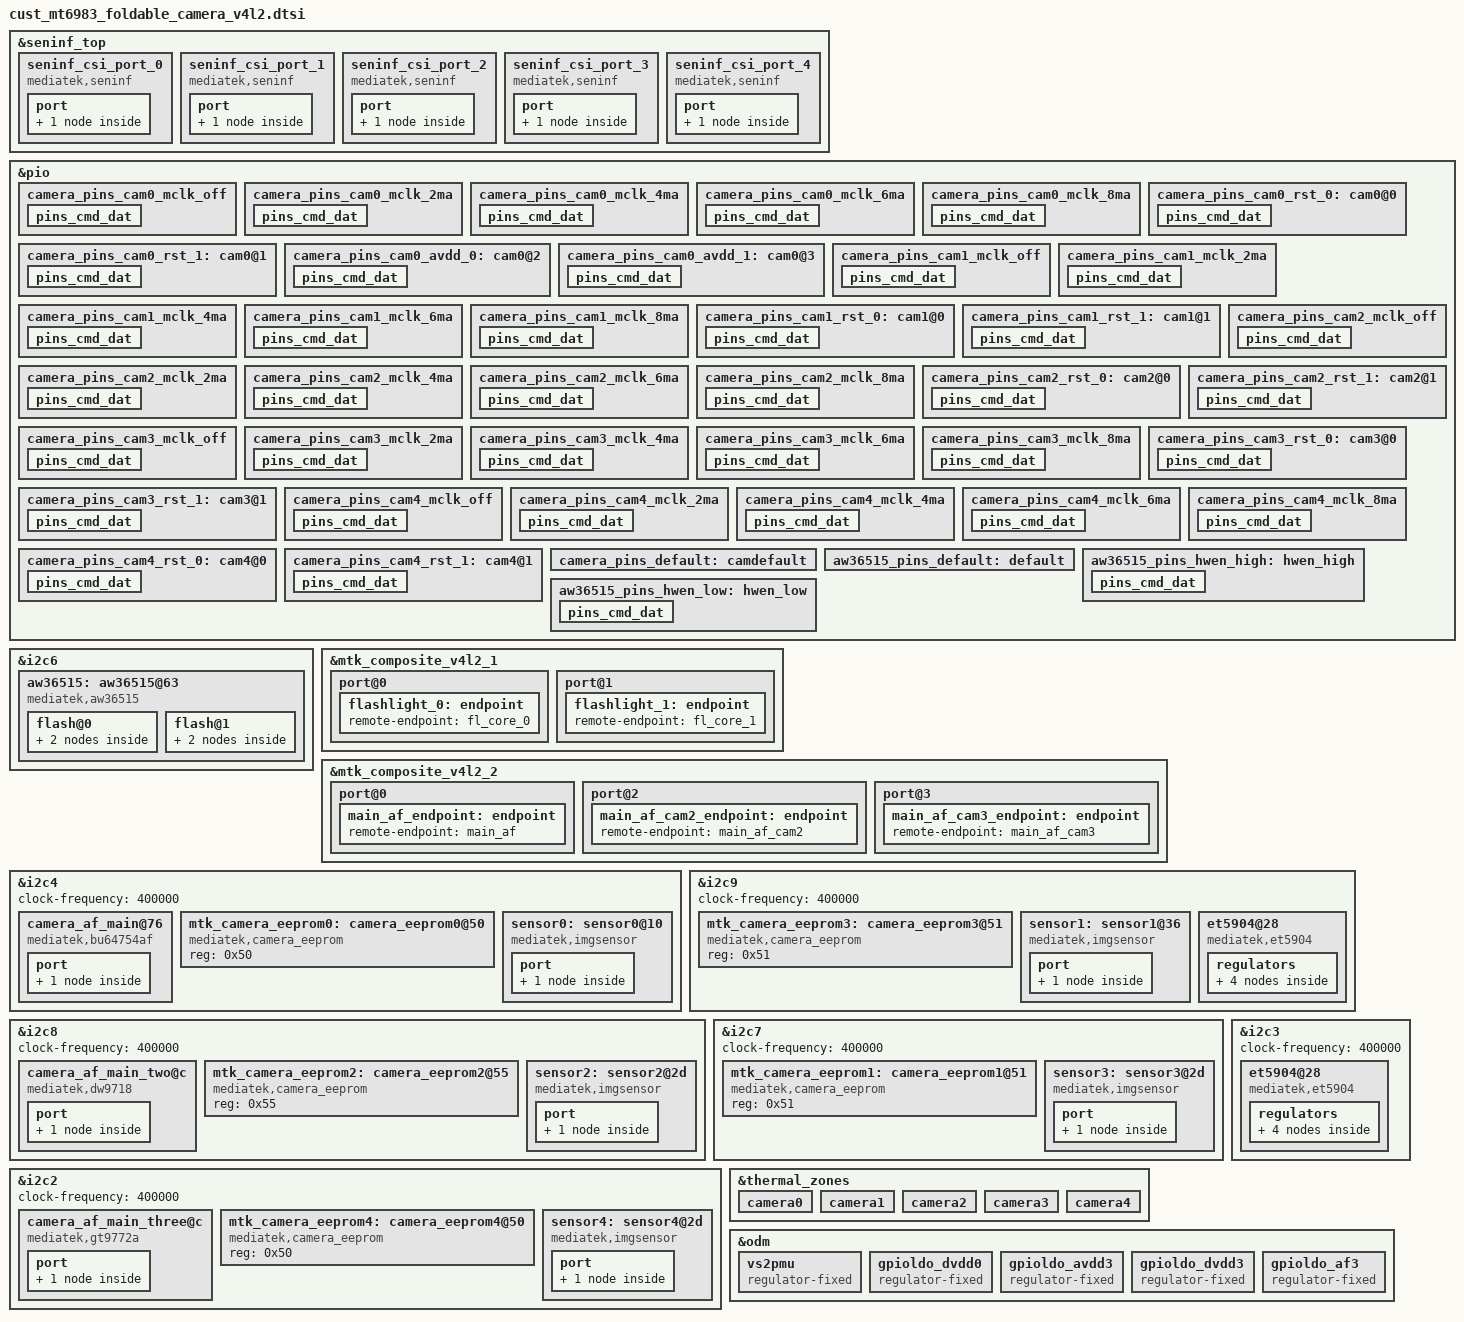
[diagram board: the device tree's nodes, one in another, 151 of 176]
// SPDX-License-Identifier: GPL-2.0
/* Copyright (c) 2020 MediaTek Inc. */

&seninf_top {
		seninf_csi_port_0: seninf_csi_port_0 {
			compatible = "mediatek,seninf";
			csi-port = "0";
			dphy_settle_delay_dt = <17>;
			nvmem-cells = <&csi_efuse0>;
			nvmem-cell-names = "rg_csi";
			port {
				seninf_csi_port_0_in: endpoint {
					remote-endpoint = <&sensor3_out>;
				};
			};
		};

		seninf_csi_port_1: seninf_csi_port_1 {
			compatible = "mediatek,seninf";
			csi-port = "1";
			hs_trail_parameter = <0x20>;
			nvmem-cells = <&csi_efuse1>;
			nvmem-cell-names = "rg_csi";
			port {
				seninf_csi_port_1_in: endpoint {
					remote-endpoint = <&sensor1_out>;
				};
			};
		};
		seninf_csi_port_2: seninf_csi_port_2 {
			compatible = "mediatek,seninf";
			csi-port = "2";
			hs_trail_parameter = <0x20>;
			nvmem-cells = <&csi_efuse2>;
			nvmem-cell-names = "rg_csi";
			port {
				seninf_csi_port_2_in: endpoint {
					remote-endpoint = <&sensor4_out>;
				};
			};
		};
		seninf_csi_port_3: seninf_csi_port_3 {
			compatible = "mediatek,seninf";
			csi-port = "3";
			nvmem-cells = <&csi_efuse3>;
			nvmem-cell-names = "rg_csi";
			port {
				seninf_csi_port_3_in: endpoint {
					remote-endpoint = <&sensor0_out>;
				};
			};
		};
		seninf_csi_port_4: seninf_csi_port_4 {
			compatible = "mediatek,seninf";
			csi-port = "4";
			nvmem-cells = <&csi_efuse1>;
			nvmem-cell-names = "rg_csi";
			port {
				seninf_csi_port_4_in: endpoint {
					remote-endpoint = <&sensor2_out>;
				};
			};
		};
};
/* CAMERA GPIO standardization */
&pio {
	camera_pins_cam0_mclk_off: camera_pins_cam0_mclk_off {
		pins_cmd_dat {
			pinmux = <PINMUX_GPIO197__FUNC_GPIO197>;
			drive-strength = <1>;
		};
	};
	camera_pins_cam0_mclk_2ma: camera_pins_cam0_mclk_2ma {
		pins_cmd_dat {
			pinmux = <PINMUX_GPIO197__FUNC_CMMCLK1>;
			drive-strength = <0>;
		};
	};
	camera_pins_cam0_mclk_4ma: camera_pins_cam0_mclk_4ma {
		pins_cmd_dat {
			pinmux = <PINMUX_GPIO197__FUNC_CMMCLK1>;
			drive-strength = <1>;
		};
	};
	camera_pins_cam0_mclk_6ma: camera_pins_cam0_mclk_6ma {
		pins_cmd_dat {
			pinmux = <PINMUX_GPIO197__FUNC_CMMCLK1>;
			drive-strength = <2>;
		};
	};
	camera_pins_cam0_mclk_8ma: camera_pins_cam0_mclk_8ma {
		pins_cmd_dat {
			pinmux = <PINMUX_GPIO197__FUNC_CMMCLK1>;
			drive-strength = <3>;
		};
	};
	camera_pins_cam0_rst_0: cam0@0 {
		pins_cmd_dat {
			pinmux = <PINMUX_GPIO200__FUNC_GPIO200>;
			slew-rate = <1>;
			output-low;
		};
	};
	camera_pins_cam0_rst_1: cam0@1 {
		pins_cmd_dat {
			pinmux = <PINMUX_GPIO200__FUNC_GPIO200>;
			slew-rate = <1>;
			output-high;
		};
	};
	camera_pins_cam0_avdd_0: cam0@2 {
		pins_cmd_dat {
			pinmux = <PINMUX_GPIO188__FUNC_GPIO188>;
			slew-rate = <1>;
			output-low;
		};
	};
	camera_pins_cam0_avdd_1: cam0@3 {
		pins_cmd_dat {
			pinmux = <PINMUX_GPIO188__FUNC_GPIO188>;
			slew-rate = <1>;
			output-high;
		};
	};

	camera_pins_cam1_mclk_off: camera_pins_cam1_mclk_off {
		pins_cmd_dat {
			pinmux = <PINMUX_GPIO209__FUNC_GPIO209>;
			drive-strength = <1>;
		};
	};
	camera_pins_cam1_mclk_2ma: camera_pins_cam1_mclk_2ma {
		pins_cmd_dat {
			pinmux = <PINMUX_GPIO209__FUNC_CMMCLK4>;
			drive-strength = <0>;
		};
	};
	camera_pins_cam1_mclk_4ma: camera_pins_cam1_mclk_4ma {
		pins_cmd_dat {
			pinmux = <PINMUX_GPIO209__FUNC_CMMCLK4>;
			drive-strength = <1>;
		};
	};
	camera_pins_cam1_mclk_6ma: camera_pins_cam1_mclk_6ma {
		pins_cmd_dat {
			pinmux = <PINMUX_GPIO209__FUNC_CMMCLK4>;
			drive-strength = <2>;
		};
	};
	camera_pins_cam1_mclk_8ma: camera_pins_cam1_mclk_8ma {
		pins_cmd_dat {
			pinmux = <PINMUX_GPIO209__FUNC_CMMCLK4>;
			drive-strength = <3>;
		};
	};
	camera_pins_cam1_rst_0: cam1@0 {
		pins_cmd_dat {
			pinmux = <PINMUX_GPIO203__FUNC_GPIO203>;
			slew-rate = <1>;
			output-low;
		};
	};
	camera_pins_cam1_rst_1: cam1@1 {
		pins_cmd_dat {
			pinmux = <PINMUX_GPIO203__FUNC_GPIO203>;
			slew-rate = <1>;
			output-high;
		};
	};

	camera_pins_cam2_mclk_off: camera_pins_cam2_mclk_off {
		pins_cmd_dat {
			pinmux = <PINMUX_GPIO198__FUNC_GPIO198>;
			drive-strength = <1>;
		};
	};
	camera_pins_cam2_mclk_2ma: camera_pins_cam2_mclk_2ma {
		pins_cmd_dat {
			pinmux = <PINMUX_GPIO198__FUNC_CMMCLK2>;
			drive-strength = <0>;
		};
	};
	camera_pins_cam2_mclk_4ma: camera_pins_cam2_mclk_4ma {
		pins_cmd_dat {
			pinmux = <PINMUX_GPIO198__FUNC_CMMCLK2>;
			drive-strength = <1>;
		};
	};
	camera_pins_cam2_mclk_6ma: camera_pins_cam2_mclk_6ma {
		pins_cmd_dat {
			pinmux = <PINMUX_GPIO198__FUNC_CMMCLK2>;
			drive-strength = <2>;
		};
	};
	camera_pins_cam2_mclk_8ma: camera_pins_cam2_mclk_8ma {
		pins_cmd_dat {
			pinmux = <PINMUX_GPIO198__FUNC_CMMCLK2>;
			drive-strength = <3>;
		};
	};
	camera_pins_cam2_rst_0: cam2@0 {
		pins_cmd_dat {
			pinmux = <PINMUX_GPIO201__FUNC_GPIO201>;
			slew-rate = <1>;
			output-low;
		};
	};
	camera_pins_cam2_rst_1: cam2@1 {
		pins_cmd_dat {
			pinmux = <PINMUX_GPIO201__FUNC_GPIO201>;
			slew-rate = <1>;
			output-high;
		};
	};

	camera_pins_cam3_mclk_off: camera_pins_cam3_mclk_off {
		pins_cmd_dat {
			pinmux = <PINMUX_GPIO196__FUNC_GPIO196>;
			drive-strength = <1>;
		};
	};
	camera_pins_cam3_mclk_2ma: camera_pins_cam3_mclk_2ma {
		pins_cmd_dat {
			pinmux = <PINMUX_GPIO196__FUNC_CMMCLK0>;
			drive-strength = <0>;
		};
	};
	camera_pins_cam3_mclk_4ma: camera_pins_cam3_mclk_4ma {
		pins_cmd_dat {
			pinmux = <PINMUX_GPIO196__FUNC_CMMCLK0>;
			drive-strength = <1>;
		};
	};
	camera_pins_cam3_mclk_6ma: camera_pins_cam3_mclk_6ma {
		pins_cmd_dat {
			pinmux = <PINMUX_GPIO196__FUNC_CMMCLK0>;
			drive-strength = <2>;
		};
	};
	camera_pins_cam3_mclk_8ma: camera_pins_cam3_mclk_8ma {
		pins_cmd_dat {
			pinmux = <PINMUX_GPIO196__FUNC_CMMCLK0>;
			drive-strength = <3>;
		};
	};
	camera_pins_cam3_rst_0: cam3@0 {
		pins_cmd_dat {
			pinmux = <PINMUX_GPIO199__FUNC_GPIO199>;
			slew-rate = <1>;
			output-low;
		};
	};
	camera_pins_cam3_rst_1: cam3@1 {
		pins_cmd_dat {
			pinmux = <PINMUX_GPIO199__FUNC_GPIO199>;
			slew-rate = <1>;
			output-high;
		};
	};

	camera_pins_cam4_mclk_off: camera_pins_cam4_mclk_off {
		pins_cmd_dat {
			pinmux = <PINMUX_GPIO208__FUNC_GPIO208>;
			drive-strength = <1>;
		};
	};
	camera_pins_cam4_mclk_2ma: camera_pins_cam4_mclk_2ma {
		pins_cmd_dat {
			pinmux = <PINMUX_GPIO208__FUNC_CMMCLK3>;
			drive-strength = <0>;
		};
	};
	camera_pins_cam4_mclk_4ma: camera_pins_cam4_mclk_4ma {
		pins_cmd_dat {
			pinmux = <PINMUX_GPIO208__FUNC_CMMCLK3>;
			drive-strength = <1>;
		};
	};
	camera_pins_cam4_mclk_6ma: camera_pins_cam4_mclk_6ma {
		pins_cmd_dat {
			pinmux = <PINMUX_GPIO208__FUNC_CMMCLK3>;
			drive-strength = <2>;
		};
	};
	camera_pins_cam4_mclk_8ma: camera_pins_cam4_mclk_8ma {
		pins_cmd_dat {
			pinmux = <PINMUX_GPIO208__FUNC_CMMCLK3>;
			drive-strength = <3>;
		};
	};
	camera_pins_cam4_rst_0: cam4@0 {
		pins_cmd_dat {
			pinmux = <PINMUX_GPIO202__FUNC_GPIO202>;
			slew-rate = <1>;
			output-low;
		};
	};
	camera_pins_cam4_rst_1: cam4@1 {
		pins_cmd_dat {
			pinmux = <PINMUX_GPIO202__FUNC_GPIO202>;
			slew-rate = <1>;
			output-high;
		};
	};
	camera_pins_default: camdefault {
	};
};
/* CAMERA GPIO end */

&i2c6 {
	aw36515:aw36515@63 {
		compatible = "mediatek,aw36515";
		reg = <0x63>;
		#cooling-cells = <2>;
		pinctrl-names = "default", "hwen_high", "hwen_low";
		pinctrl-0 = <&aw36515_pins_default>;
		pinctrl-1 = <&aw36515_pins_hwen_high>;
		pinctrl-2 = <&aw36515_pins_hwen_low>;
		status = "okay";
		flash@0{
			reg = <1>;
			type = <1>;
			ct = <0>;
			part = <0>;
			port@0 {
				fl_core_0: endpoint {
					remote-endpoint = <&flashlight_0>;
				};
			};
		};
		flash@1{
			reg = <0>;
			type = <0>;
			ct = <0>;
			part = <0>;
			port@1 {
				fl_core_1: endpoint {
					remote-endpoint = <&flashlight_1>;
				};
			};
		};
	};
};

&pio {
	aw36515_pins_default: default {
	};

	aw36515_pins_hwen_high: hwen_high {
		pins_cmd_dat {
			pinmux = <PINMUX_GPIO31__FUNC_GPIO31>;
			slew-rate = <1>;
			output-high;
		};
	};

	aw36515_pins_hwen_low: hwen_low {
		pins_cmd_dat {
			pinmux = <PINMUX_GPIO31__FUNC_GPIO31>;
			slew-rate = <1>;
			output-low;
		};
	};
};

&mtk_composite_v4l2_1 {
	port@0 {
		flashlight_0: endpoint {
			remote-endpoint = <&fl_core_0>;
		};
	};
	port@1 {
		flashlight_1: endpoint {
			remote-endpoint = <&fl_core_1>;
		};
	};
};

&mtk_composite_v4l2_2 {
	port@0 {
		main_af_endpoint: endpoint {
			remote-endpoint = <&main_af>;
		};
	};
	port@2 {
		main_af_cam2_endpoint: endpoint {
			remote-endpoint = <&main_af_cam2>;
		};
	};
	port@3 {
		main_af_cam3_endpoint: endpoint {
			remote-endpoint = <&main_af_cam3>;
		};
	};
};

&i2c4 {
	status = "okay";
	clock-frequency = <400000>;
	#address-cells = <1>;
	#size-cells = <0>;

	camera_af_main@76 {
		compatible = "mediatek,bu64754af";
		reg = <0x76>;
		vin-supply = <&mt6373_vibr>;
		port {
			main_af: endpoint {
				remote-endpoint = <&main_af_endpoint>;
			};
		};
	};
	mtk_camera_eeprom0:camera_eeprom0@50 {
		compatible = "mediatek,camera_eeprom";
		reg = <0x50>;
		status = "okay";
	};

	sensor0: sensor0@10 {
		compatible = "mediatek,imgsensor";
		sensor-names = "s5kgnvsp_mipi_raw";
		reg = <0x10>;
		#thermal-sensor-cells = <0>;
		sensor-matecodes = "s5kgnvsp_17201758";
		pinctrl-names = "mclk_off",
				"mclk_2mA",
				"mclk_4mA",
				"mclk_6mA",
				"mclk_8mA",
				"rst_low",
				"rst_high",
				"avdd_off",
				"avdd_on";

		pinctrl-0 = <&camera_pins_cam0_mclk_off>;
		pinctrl-1 = <&camera_pins_cam0_mclk_2ma>;
		pinctrl-2 = <&camera_pins_cam0_mclk_4ma>;
		pinctrl-3 = <&camera_pins_cam0_mclk_6ma>;
		pinctrl-4 = <&camera_pins_cam0_mclk_8ma>;
		pinctrl-5 = <&camera_pins_cam0_rst_0>;
		pinctrl-6 = <&camera_pins_cam0_rst_1>;
		pinctrl-7 = <&camera_pins_cam0_avdd_0>;
		pinctrl-8 = <&camera_pins_cam0_avdd_1>;

		dvdd-supply = <&gpioldo_dvdd0>;
		dovdd-supply = <&mt6373_vaud18>;

		clocks = <&topckgen_clk CLK_TOPCKGEN_UNIVPLL_192M_D32>,
			<&topckgen_clk CLK_TOPCKGEN_UNIVPLL_192M_D16>,
			<&topckgen_clk CLK_TOPCKGEN_F_F26M_CK_D2>,
			<&topckgen_clk CLK_TOPCKGEN_UNIVPLL_192M_D10>,
			<&topckgen_clk CLK_TOPCKGEN_UNIVPLL_192M_D8>,
			<&topckgen_clk CLK_TOP_TCK_26M_MX9>,
			<&topckgen_clk CLK_TOPCKGEN_UNIVPLL_D6_D8>,
			<&topckgen_clk CLK_TOPCKGEN_CAMTG2_SEL>;
		clock-names = "6", "12", "13", "19.2", "24", "26", "52", "mclk";

		status = "okay";

		port {
			sensor0_out: endpoint {
				remote-endpoint = <&seninf_csi_port_3_in>;
			};
		};
	};
};

&i2c9 {
	status = "okay";
	clock-frequency = <400000>;
	#address-cells = <1>;
	#size-cells = <0>;

	mtk_camera_eeprom3:camera_eeprom3@51 {
		compatible = "mediatek,camera_eeprom";
		reg = <0x51>;
		status = "okay";
	};

	sensor1: sensor1@36 {
		compatible = "mediatek,imgsensor";
		sensor-names = "ov16b10ff_mipi_raw";
		reg = <0x36>;
		sensor-matecodes = "ov16b10_17201705";
		#thermal-sensor-cells = <0>;
		pinctrl-names = "mclk_off",
				"mclk_2mA",
				"mclk_4mA",
				"mclk_6mA",
				"mclk_8mA",
				"rst_low",
				"rst_high";

		pinctrl-0 = <&camera_pins_cam1_mclk_off>;
		pinctrl-1 = <&camera_pins_cam1_mclk_2ma>;
		pinctrl-2 = <&camera_pins_cam1_mclk_4ma>;
		pinctrl-3 = <&camera_pins_cam1_mclk_6ma>;
		pinctrl-4 = <&camera_pins_cam1_mclk_8ma>;
		pinctrl-5 = <&camera_pins_cam1_rst_0>;
		pinctrl-6 = <&camera_pins_cam1_rst_1>;

		avdd-supply = <&et5904ldo39>;
		dvdd-supply = <&et5904ldo19>;
		dovdd-supply = <&mt6373_vaud18>;

		clocks = <&topckgen_clk CLK_TOPCKGEN_UNIVPLL_192M_D32>,
			<&topckgen_clk CLK_TOPCKGEN_UNIVPLL_192M_D16>,
			<&topckgen_clk CLK_TOPCKGEN_F_F26M_CK_D2>,
			<&topckgen_clk CLK_TOPCKGEN_UNIVPLL_192M_D10>,
			<&topckgen_clk CLK_TOPCKGEN_UNIVPLL_192M_D8>,
			<&topckgen_clk CLK_TOP_TCK_26M_MX9>,
			<&topckgen_clk CLK_TOPCKGEN_UNIVPLL_D6_D8>,
			<&topckgen_clk CLK_TOPCKGEN_CAMTG5_SEL>;
		clock-names = "6", "12", "13", "19.2", "24", "26", "52", "mclk";

		status = "okay";

		port {
			sensor1_out: endpoint {
				remote-endpoint = <&seninf_csi_port_1_in>;
			};
		};
	};
};

&i2c8 {
	status = "okay";
	clock-frequency = <400000>;
	#address-cells = <1>;
	#size-cells = <0>;

	camera_af_main_two@c {
		compatible = "mediatek,dw9718";
		reg = <0x0c>;
		vin-supply = <&et5904ldo43>;
		port {
			main_af_cam2: endpoint {
				remote-endpoint = <&main_af_cam2_endpoint>;
			};
		};
	};

	mtk_camera_eeprom2:camera_eeprom2@55 {
		compatible = "mediatek,camera_eeprom";
		reg = <0x55>;
		status = "okay";
	};

	sensor2: sensor2@2d {
		compatible = "mediatek,imgsensor";
		sensor-names = "s5kjn1tele_mipi_raw";
		reg = <0x2d>;
		sensor-matecodes = "s5kjn1tele_17201764";
		#thermal-sensor-cells = <0>;
		pinctrl-names = "mclk_off",
				"mclk_2mA",
				"mclk_4mA",
				"mclk_6mA",
				"mclk_8mA",
				"rst_low",
				"rst_high";

		pinctrl-0 = <&camera_pins_cam2_mclk_off>;
		pinctrl-1 = <&camera_pins_cam2_mclk_2ma>;
		pinctrl-2 = <&camera_pins_cam2_mclk_4ma>;
		pinctrl-3 = <&camera_pins_cam2_mclk_6ma>;
		pinctrl-4 = <&camera_pins_cam2_mclk_8ma>;
		pinctrl-5 = <&camera_pins_cam2_rst_0>;
		pinctrl-6 = <&camera_pins_cam2_rst_1>;

		avdd-supply = <&et5904ldo49>;
		dvdd-supply = <&et5904ldo29>;
		dovdd-supply = <&mt6373_vaud18>;

		clocks = <&topckgen_clk CLK_TOPCKGEN_UNIVPLL_192M_D32>,
			<&topckgen_clk CLK_TOPCKGEN_UNIVPLL_192M_D16>,
			<&topckgen_clk CLK_TOPCKGEN_F_F26M_CK_D2>,
			<&topckgen_clk CLK_TOPCKGEN_UNIVPLL_192M_D10>,
			<&topckgen_clk CLK_TOPCKGEN_UNIVPLL_192M_D8>,
			<&topckgen_clk CLK_TOP_TCK_26M_MX9>,
			<&topckgen_clk CLK_TOPCKGEN_UNIVPLL_D6_D8>,
			<&topckgen_clk CLK_TOPCKGEN_CAMTG3_SEL>;
		clock-names = "6", "12", "13", "19.2", "24", "26", "52", "mclk";

		status = "okay";

		port {
			sensor2_out: endpoint {
				remote-endpoint = <&seninf_csi_port_4_in>;
			};
		};
	};
};

&i2c7 {
	status = "okay";
	clock-frequency = <400000>;
	#address-cells = <1>;
	#size-cells = <0>;

	mtk_camera_eeprom1:camera_eeprom1@51 {
		compatible = "mediatek,camera_eeprom";
		reg = <0x51>;
		status = "okay";
	};

	sensor3: sensor3@2d {
		compatible = "mediatek,imgsensor";
		sensor-names = "s5kgd2sp_mipi_raw";
		reg = <0x2d>;
		#thermal-sensor-cells = <0>;
		sensor-matecodes = "s5kgd2sp_17201766";
		pinctrl-names = "mclk_off",
				"mclk_2mA",
				"mclk_4mA",
				"mclk_6mA",
				"mclk_8mA",
				"rst_low",
				"rst_high";

		pinctrl-0 = <&camera_pins_cam3_mclk_off>;
		pinctrl-1 = <&camera_pins_cam3_mclk_2ma>;
		pinctrl-2 = <&camera_pins_cam3_mclk_4ma>;
		pinctrl-3 = <&camera_pins_cam3_mclk_6ma>;
		pinctrl-4 = <&camera_pins_cam3_mclk_8ma>;
		pinctrl-5 = <&camera_pins_cam3_rst_0>;
		pinctrl-6 = <&camera_pins_cam3_rst_1>;

		avdd-supply = <&gpioldo_avdd3>;
		dvdd-supply = <&gpioldo_dvdd3>;
		dovdd-supply = <&mt6373_vcn18io>;

		clocks = <&topckgen_clk CLK_TOPCKGEN_UNIVPLL_192M_D32>,
			<&topckgen_clk CLK_TOPCKGEN_UNIVPLL_192M_D16>,
			<&topckgen_clk CLK_TOPCKGEN_F_F26M_CK_D2>,
			<&topckgen_clk CLK_TOPCKGEN_UNIVPLL_192M_D10>,
			<&topckgen_clk CLK_TOPCKGEN_UNIVPLL_192M_D8>,
			<&topckgen_clk CLK_TOP_TCK_26M_MX9>,
			<&topckgen_clk CLK_TOPCKGEN_UNIVPLL_D6_D8>,
			<&topckgen_clk CLK_TOPCKGEN_CAMTG_SEL>;
		clock-names = "6", "12", "13", "19.2", "24", "26", "52", "mclk";

		status = "okay";

		port {
			sensor3_out: endpoint {
				remote-endpoint = <&seninf_csi_port_0_in>;
			};
		};
	};
};

&i2c2 {
	status = "okay";
	clock-frequency = <400000>;
	#address-cells = <1>;
	#size-cells = <0>;
	camera_af_main_three@c {
		compatible = "mediatek,gt9772a";
		reg = <0x0c>;
		vin-supply = <&gpioldo_af3>;
		port {
			main_af_cam3: endpoint {
				remote-endpoint = <&main_af_cam3_endpoint>;
			};
		};
	};
	mtk_camera_eeprom4:camera_eeprom4@50 {
		compatible = "mediatek,camera_eeprom";
		reg = <0x50>;
		status = "okay";
	};

	sensor4: sensor4@2d {
		compatible = "mediatek,imgsensor";
		sensor-names = "s5k3l6wide_mipi_raw";
		reg = <0x2d>;
		sensor-matecodes = "s5k3l6wide_17201737";
		#thermal-sensor-cells = <0>;
		pinctrl-names = "mclk_off",
				"mclk_2mA",
				"mclk_4mA",
				"mclk_6mA",
				"mclk_8mA",
				"rst_low",
				"rst_high";

		pinctrl-0 = <&camera_pins_cam4_mclk_off>;
		pinctrl-1 = <&camera_pins_cam4_mclk_2ma>;
		pinctrl-2 = <&camera_pins_cam4_mclk_4ma>;
		pinctrl-3 = <&camera_pins_cam4_mclk_6ma>;
		pinctrl-4 = <&camera_pins_cam4_mclk_8ma>;
		pinctrl-5 = <&camera_pins_cam4_rst_0>;
		pinctrl-6 = <&camera_pins_cam4_rst_1>;

		avdd-supply = <&et5904ldo33>;
		dvdd-supply = <&et5904ldo13>;
		dovdd-supply = <&mt6373_vaud18>;

		clocks = <&topckgen_clk CLK_TOPCKGEN_UNIVPLL_192M_D32>,
			<&topckgen_clk CLK_TOPCKGEN_UNIVPLL_192M_D16>,
			<&topckgen_clk CLK_TOPCKGEN_F_F26M_CK_D2>,
			<&topckgen_clk CLK_TOPCKGEN_UNIVPLL_192M_D10>,
			<&topckgen_clk CLK_TOPCKGEN_UNIVPLL_192M_D8>,
			<&topckgen_clk CLK_TOP_TCK_26M_MX9>,
			<&topckgen_clk CLK_TOPCKGEN_UNIVPLL_D6_D8>,
			<&topckgen_clk CLK_TOPCKGEN_CAMTG4_SEL>;
		clock-names = "6", "12", "13", "19.2", "24", "26", "52", "mclk";

		status = "okay";

		port {
			sensor4_out: endpoint {
				remote-endpoint = <&seninf_csi_port_2_in>;
			};
		};
	};
};

&thermal_zones {
		camera0: camera0 {
			polling-delay = <0>; /* milliseconds */
			polling-delay-passive = <0>; /* milliseconds */
			thermal-sensors = <&sensor0>;
		};
		camera1: camera1 {
			polling-delay = <0>; /* milliseconds */
			polling-delay-passive = <0>; /* milliseconds */
			thermal-sensors = <&sensor1>;
		};
		camera2: camera2 {
			polling-delay = <0>; /* milliseconds */
			polling-delay-passive = <0>; /* milliseconds */
			thermal-sensors = <&sensor2>;
		};
		camera3: camera3 {
			polling-delay = <0>; /* milliseconds */
			polling-delay-passive = <0>; /* milliseconds */
			thermal-sensors = <&sensor3>;
		};
		camera4: camera4 {
			polling-delay = <0>; /* milliseconds */
			polling-delay-passive = <0>; /* milliseconds */
			thermal-sensors = <&sensor4>;
		};
};

&i2c3 {
	status = "okay";
	clock-frequency = <400000>;
	#address-cells = <1>;
	#size-cells = <0>;

	et5904@28 {
		compatible = "mediatek,et5904";
		reg = <0x28>;
		vina-supply = <&vs2pmu>;
		regulators {
			et5904ldo13:et5904ldo13 {
				regulator-name = "ET5904LDO13";
				regulator-min-microvolt = <600000>;
				regulator-max-microvolt = <1800000>;
			};
			et5904ldo23:et5904ldo23 {
				regulator-name = "ET5904LDO23";
				regulator-min-microvolt = <1200000>;
				regulator-max-microvolt = <1200000>;
				regulator-always-on;
			};
			et5904ldo33:et5904ldo33 {
				regulator-name = "ET5904LDO33";
				regulator-min-microvolt = <1200000>;
				regulator-max-microvolt = <2800000>;
			};
			et5904ldo43:et5904ldo43 {
				regulator-name = "ET5904LDO43";
				regulator-min-microvolt = <1200000>;
				regulator-max-microvolt = <2800000>;
			};
		};
	};
};

&i2c9 {
	#address-cells = <1>;
	#size-cells = <0>;

	et5904@28 {
		compatible = "mediatek,et5904";
		reg = <0x28>;
		vina-supply = <&vs2pmu>;
		regulators {
			et5904ldo19:et5904ldo19 {
				regulator-name = "ET5904LDO19";
				regulator-min-microvolt = <600000>;
				regulator-max-microvolt = <1800000>;
			};
			et5904ldo29:et5904ldo29 {
				regulator-name = "ET5904LDO29";
				regulator-min-microvolt = <600000>;
				regulator-max-microvolt = <1800000>;
			};
			et5904ldo39:et5904ldo39 {
				regulator-name = "ET5904LDO39";
				regulator-min-microvolt = <1200000>;
				regulator-max-microvolt = <2800000>;
			};
			et5904ldo49:et5904ldo49 {
				regulator-name = "ET5904LDO49";
				regulator-min-microvolt = <1200000>;
				regulator-max-microvolt = <2800000>;
			};
		};
	};
};

&odm {
	vs2pmu: vs2pmu {
		compatible = "regulator-fixed";
		regulator-name = "vs2pmu";
		regulator-min-microvolt = <1800000>;
		regulator-max-microvolt = <1800000>;
		gpio = <&pio 187 0x0>;
		enable-active-high;
		regulator-always-on;
		regulator-boot-on;
	};
	gpioldo_dvdd0: gpioldo_dvdd0 {
		compatible = "regulator-fixed";
		regulator-name = "gpioldo_dvdd0";
		regulator-min-microvolt = <1050000>;
		regulator-max-microvolt = <1050000>;
		gpio = <&pio 195 0x0>;
		enable-active-high;
		regulator-boot-on;
		vin-supply = <&vs2pmu>;
	};

	gpioldo_avdd3: gpioldo_avdd3 {
		compatible = "regulator-fixed";
		regulator-name = "gpioldo_avdd3";
		regulator-min-microvolt = <2800000>;
		regulator-max-microvolt = <2800000>;
		gpio = <&pio 148 0x0>;
		enable-active-high;
		regulator-boot-on;
	};

	gpioldo_dvdd3: gpioldo_dvdd3 {
		compatible = "regulator-fixed";
		regulator-name = "gpioldo_dvdd3";
		regulator-min-microvolt = <1050000>;
		regulator-max-microvolt = <1050000>;
		gpio = <&pio 165 0x0>;
		enable-active-high;
		regulator-boot-on;
		vin-supply = <&vs2pmu>;
	};

	gpioldo_af3: gpioldo_af3 {
		compatible = "regulator-fixed";
		regulator-name = "gpioldo_af3";
		regulator-min-microvolt = <2800000>;
		regulator-max-microvolt = <2800000>;
		gpio = <&pio 204 0x0>;
		enable-active-high;
		regulator-always-on;
	};
};
